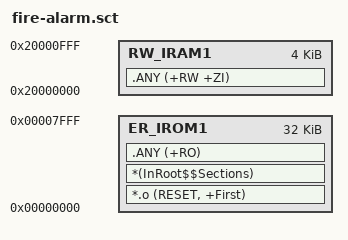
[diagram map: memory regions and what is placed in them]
LR_IROM1 0x00000000 0x00008000  {    ; 32KB Flash
  ER_IROM1 0x00000000 0x00008000  {
    *.o (RESET, +First)
    *(InRoot$$Sections)
    .ANY (+RO)
  }
  RW_IRAM1 0x20000000 0x00001000  {  ; 4KB RAM
    .ANY (+RW +ZI)
  }
}
